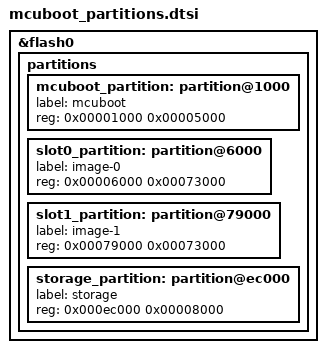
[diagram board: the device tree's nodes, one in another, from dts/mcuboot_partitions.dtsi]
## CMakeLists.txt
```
# SPDX-License-Identifier: MIT

cmake_minimum_required(VERSION 3.20.0)

# The Sense Plus shares the XIAO BLE Sense board definition (same nRF52840,
# LEDs, IMU and mic; the Plus only adds extra pads on the underside).
if(NOT DEFINED BOARD)
  set(BOARD xiao_ble/nrf52840/sense)
endif()

find_package(Zephyr REQUIRED HINTS $ENV{ZEPHYR_BASE})
project(xiao_nrf52840_sense_plus)

target_sources(app PRIVATE
  src/main.c
  src/ble_shell.c
  src/blink.c
  src/bonds.c
  src/crash.c
  src/files.c
  src/hid.c
  src/imu.c
  src/sleep.c
)
```

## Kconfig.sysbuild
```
# SPDX-License-Identifier: MIT

# Sign images with the project's key, an ECDSA P-256 private key in PEM format.
# It is taken from the MCUBOOT_SIGNING_KEY environment variable (a path) or,
# when that is not set, from its usual place in the home directory. With
# neither, the build falls back to MCUboot's public development key.
PROJECT_KEY := $(shell,ls ~/.mcuboot/cato2.pem 2>/dev/null)

config BOOT_SIGNATURE_KEY_FILE
	default "$(MCUBOOT_SIGNING_KEY)" if "$(MCUBOOT_SIGNING_KEY)" != ""
	default "$(PROJECT_KEY)" if "$(PROJECT_KEY)" != ""

source "share/sysbuild/Kconfig"
```

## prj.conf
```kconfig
CONFIG_LOG=y

# Bluetooth LE peripheral
CONFIG_BT=y
CONFIG_BT_PERIPHERAL=y
# Until the board has a name of its own: at first boot it becomes Cato_xxxx,
# from the last four digits of its serial number (src/main.c).
CONFIG_BT_DEVICE_NAME="Cato"
# "name" shell command. 26 characters is what fits in the advertising packet.
CONFIG_BT_DEVICE_NAME_DYNAMIC=y
CONFIG_BT_DEVICE_NAME_MAX=26
# The shell prompt is the name followed by ":~$ ".
CONFIG_SHELL_PROMPT_CHANGE=y
CONFIG_SHELL_PROMPT_BUFF_SIZE=32

# Up to three devices at once, so that a computer using the board as a mouse
# or keyboard does not shut out the console and OTA from another device
CONFIG_BT_MAX_CONN=3

# HID over GATT: mouse, keyboard and sensor reports, in two HID services
# (src/hid.c)
CONFIG_BT_HIDS=y
CONFIG_BT_CONN_CTX=y
CONFIG_BT_HIDS_MAX_CLIENT_COUNT=3
CONFIG_BT_HIDS_ATTR_MAX=30
# Pools the service allocates its attributes from. Too small and the service
# is silently registered incomplete, and hosts then ignore it.
CONFIG_BT_GATT_UUID16_POOL_SIZE=80
CONFIG_BT_GATT_CHRC_POOL_SIZE=24
CONFIG_BT_HIDS_DEFAULT_PERM_RW_ENCRYPT=y
# Ask hosts for an 11.25 ms connection interval, the shortest that Apple hosts
# grant (and only to HID devices). Mouse movement and the sensor report rate
# depend on it. A host that refuses simply keeps its own interval.
CONFIG_BT_PERIPHERAL_PREF_MIN_INT=9
CONFIG_BT_PERIPHERAL_PREF_MAX_INT=9
CONFIG_BT_PERIPHERAL_PREF_LATENCY=0
CONFIG_BT_PERIPHERAL_PREF_TIMEOUT=400
# Several reports per connection event: pack the reports queued within a
# millisecond into one packet for hosts that support it, and ask for the 2 Mbit
# radio mode, which halves the time each packet takes
CONFIG_BT_GATT_NOTIFY_MULTIPLE=y
CONFIG_BT_USER_PHY_UPDATE=y
# Largest packets: ask each host for a 498-byte ATT MTU (the default is 23)
CONFIG_BT_L2CAP_TX_MTU=498
CONFIG_BT_BUF_ACL_RX_SIZE=502
CONFIG_BT_BUF_ACL_TX_SIZE=502
CONFIG_BT_GATT_CLIENT=y
CONFIG_BT_GATT_AUTO_UPDATE_MTU=y
# Room to queue a burst of reports between connection events
CONFIG_BT_L2CAP_TX_BUF_COUNT=8
CONFIG_BT_BUF_ACL_TX_COUNT=8
CONFIG_BT_CONN_TX_MAX=8
CONFIG_BT_CTLR_SDC_TX_PACKET_COUNT=8
# Generic Human Interface Device
CONFIG_BT_DEVICE_APPEARANCE=960
# Hosts expect a Device Information Service with a PnP ID beside HID. The IDs
# are the pid.codes test pair: replace them with your own before shipping.
CONFIG_BT_DIS=y
CONFIG_BT_DIS_PNP=y
CONFIG_BT_DIS_PNP_VID_SRC=2
CONFIG_BT_DIS_PNP_VID=0x1209
CONFIG_BT_DIS_PNP_PID=0x0001
CONFIG_BT_DIS_PNP_VER=0x0001
# The serial number is the chip's unique ID, filled in at boot (src/main.c)
CONFIG_BT_DIS_SERIAL_NUMBER=y
CONFIG_BT_DIS_SETTINGS=y
CONFIG_BT_DIS_STR_MAX=32
CONFIG_SETTINGS_RUNTIME=y
CONFIG_BT_DIS_MANUF_NAME_STR="Auli.Tech"
CONFIG_BT_DIS_MODEL_NUMBER_STR="XIAO nRF52840 Sense Plus"

# Pairing: the console and OTA services need an encrypted link. Up to five
# bonded devices are remembered across resets (see src/bonds.c).
CONFIG_BT_SMP=y
CONFIG_BT_MAX_PAIRED=5
CONFIG_BT_SETTINGS=y
CONFIG_BT_SMP_APP_PAIRING_ACCEPT=y
# Let a bonded device that has forgotten the board pair again.
CONFIG_BT_SMP_ALLOW_UNAUTH_OVERWRITE=y
CONFIG_MCUMGR_TRANSPORT_BT_PERM_RW_ENCRYPT=y

# Console: Zephyr shell (and log output) over Bluetooth (src/ble_shell.c) and
# over the USB CDC ACM serial port
CONFIG_SHELL=y
CONFIG_SHELL_BACKEND_SERIAL=y
CONFIG_RING_BUFFER=y

# "bootloader" shell command
CONFIG_REBOOT=y

# OTA firmware upgrade: MCUmgr/SMP over Bluetooth into the MCUboot secondary slot
CONFIG_NCS_SAMPLE_MCUMGR_BT_OTA_DFU=y

# On-board LSM6DS3TR-C IMU, driven directly over I2C by src/imu.c rather than
# by the Zephyr sensor driver, so that every register can be configured
CONFIG_I2C=y
CONFIG_CBPRINTF_FP_SUPPORT=y

# "sleep" shell command (System OFF), and telling a motion wake-up from a reset
CONFIG_POWEROFF=y
CONFIG_HWINFO=y

# Persistent settings (name, bonds, blink, IMU configuration) in the storage
# partition
CONFIG_FLASH=y
CONFIG_FLASH_MAP=y
CONFIG_NVS=y
CONFIG_SETTINGS=y
CONFIG_SETTINGS_NVS=y

# The Bluetooth transmit thread peaked at 676 of its default 768 bytes.
CONFIG_BT_TX_PROCESSOR_STACK_SIZE=1024

# Files: LittleFS on the 2 MB QSPI flash (src/files.c), which sleeps when idle
CONFIG_FILE_SYSTEM=y
CONFIG_FILE_SYSTEM_LITTLEFS=y
CONFIG_PM_DEVICE=y
CONFIG_PM_DEVICE_RUNTIME=y

# File transfer over Bluetooth: MCUmgr's file commands, with src/files.c
# deciding which transfers may start and told when each piece is done. Only
# sending and fetching are offered, not file status or hashes.
CONFIG_MCUMGR_GRP_FS=y
CONFIG_MCUMGR_GRP_FS_MAX_FILE_SIZE_4GB=y
CONFIG_MCUMGR_GRP_FS_FILE_STATUS=n
CONFIG_MCUMGR_GRP_FS_CHECKSUM_HASH=n
CONFIG_MCUMGR_MGMT_NOTIFICATION_HOOKS=y
CONFIG_MCUMGR_GRP_FS_FILE_ACCESS_HOOK=y
CONFIG_MCUMGR_SMP_COMMAND_STATUS_HOOKS=y
# A piece of a download is read into a buffer on the MCUmgr thread's stack.
CONFIG_MCUMGR_GRP_FS_DL_CHUNK_SIZE_LIMIT=y
CONFIG_MCUMGR_GRP_FS_DL_CHUNK_SIZE=1024
CONFIG_MCUMGR_TRANSPORT_WORKQUEUE_STACK_SIZE=6144
# The "files" commands run file system calls on the shell threads.
CONFIG_SHELL_STACK_SIZE=4096
```

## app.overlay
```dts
/* SPDX-License-Identifier: MIT */

#include "dts/mcuboot_partitions.dtsi"

/ {
	chosen {
		zephyr,code-partition = &slot0_partition;
	};
};

/*
 * The board's 2 MB QSPI flash holds a file system (src/files.c), all of it.
 * The chip is put in deep power-down whenever it is not in use.
 */
&p25q16h {
	zephyr,pm-device-runtime-auto;

	partitions {
		compatible = "fixed-partitions";
		#address-cells = <1>;
		#size-cells = <1>;

		files_partition: partition@0 {
			label = "files";
			reg = <0x00000000 0x00200000>;
		};
	};
};
```

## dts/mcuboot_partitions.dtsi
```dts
/*
 * SPDX-License-Identifier: MIT
 *
 * Flash layout: MCUboot chain-loaded by the stock Adafruit UF2 bootloader.
 *
 *   0x00000  MBR (the UF2 bootloader's, left in place)
 *   0x01000  MCUboot
 *   0x06000  slot 0: running image
 *   0x79000  slot 1: OTA download
 *   0xec000  settings storage
 *   0xf4000  Adafruit UF2 bootloader
 *
 * There is no SoftDevice: Zephyr has its own Bluetooth stack. The UF2
 * bootloader starts whatever follows the MBR when it finds none, so MCUboot
 * takes the SoftDevice's place, and writing usb-upgrade.uf2 to a board that
 * still has one overwrites it.
 *
 * MCUboot is built to be small (sysbuild/mcuboot.conf) and has the least
 * whole number of pages it fits in, with some to spare. The settings have the
 * eight pages their store uses and no more. They used to start a page lower,
 * at 0xeb000, with a ninth page that was never written: the firmware carries
 * them across the first time it starts (see storage_follow_layout() in
 * src/main.c), so they survive the move.
 *
 * Included by both the application and the MCUboot overlay so the two images
 * always agree on the layout. sysbuild.cmake names the ends of the slots too.
 */

/delete-node/ &code_partition;
/delete-node/ &storage_partition;

&flash0 {
	partitions {
		mcuboot_partition: partition@1000 {
			label = "mcuboot";
			reg = <0x00001000 0x00005000>;
		};

		slot0_partition: partition@6000 {
			label = "image-0";
			reg = <0x00006000 0x00073000>;
		};

		slot1_partition: partition@79000 {
			label = "image-1";
			reg = <0x00079000 0x00073000>;
		};

		storage_partition: partition@ec000 {
			label = "storage";
			reg = <0x000ec000 0x00008000>;
		};
	};
};
```

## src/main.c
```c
/*
 * SPDX-License-Identifier: MIT
 */

#include <ctype.h>
#include <string.h>

#include <zephyr/kernel.h>
#include <zephyr/bluetooth/bluetooth.h>
#include <zephyr/bluetooth/conn.h>
#include <zephyr/bluetooth/hci.h>
#include <zephyr/dfu/mcuboot.h>
#include <zephyr/drivers/hwinfo.h>
#include <zephyr/logging/log.h>
#include <zephyr/settings/settings.h>
#include <zephyr/shell/shell.h>
#include <zephyr/shell/shell_uart.h>
#include <zephyr/storage/flash_map.h>
#include <zephyr/sys/reboot.h>
#include <zephyr/drivers/flash.h>
#include <hal/nrf_power.h>
#include <nrfx_nvmc.h>
#include <app_version.h>

#include "app.h"

LOG_MODULE_REGISTER(app, LOG_LEVEL_INF);

/* Value the Adafruit bootloader looks for in GPREGRET to stay in UF2 mode. */
#define UF2_BOOTLOADER_MAGIC 0x57

/* How long a new connection gets to encrypt the link before it is dropped. */
#define SECURITY_TIMEOUT_MS 30000

static struct k_work adv_work;
static struct k_work_delayable security_timeout_work;

/* Connections that have not encrypted the link yet, and when they run out of time. */
static struct {
	struct bt_conn *conn;
	int64_t deadline;
} unsecured[CONFIG_BT_MAX_CONN];
static K_MUTEX_DEFINE(unsecured_lock);

static const uint8_t ad_flags[] = { BT_LE_AD_GENERAL | BT_LE_AD_NO_BREDR };

/* Scan response: the services hosts look for, and what kind of device this is. */
static const struct bt_data sd[] = {
	BT_DATA_BYTES(BT_DATA_UUID128_ALL, APP_UUID_NUS_SERVICE_VAL),
	BT_DATA_BYTES(BT_DATA_UUID16_ALL, BT_UUID_16_ENCODE(BT_UUID_HIDS_VAL)),
	BT_DATA_BYTES(BT_DATA_GAP_APPEARANCE,
		      BT_BYTES_LIST_LE16(CONFIG_BT_DEVICE_APPEARANCE)),
};

/* The advertised name can change at run time, so the data is built on demand. */
static void build_ad(struct bt_data ad[2])
{
	const char *name = bt_get_name();

	ad[0] = (struct bt_data)BT_DATA(BT_DATA_FLAGS, ad_flags, sizeof(ad_flags));
	ad[1] = (struct bt_data)BT_DATA(BT_DATA_NAME_COMPLETE, name, strlen(name));
}

/* Advertises whenever there is room for another connection. */
static void adv_work_handler(struct k_work *work)
{
	struct bt_data ad[2];
	int err;

	build_ad(ad);
	err = bt_le_adv_start(BT_LE_ADV_CONN_FAST_2, ad, ARRAY_SIZE(ad), sd, ARRAY_SIZE(sd));
	if (err && err != -EALREADY && err != -ENOMEM && err != -ECONNREFUSED) {
		LOG_ERR("Advertising failed to start (err %d)", err);
	}
}

static void unsecured_remove(struct bt_conn *conn)
{
	k_mutex_lock(&unsecured_lock, K_FOREVER);
	ARRAY_FOR_EACH(unsecured, i) {
		if (unsecured[i].conn == conn) {
			bt_conn_unref(unsecured[i].conn);
			unsecured[i].conn = NULL;
		}
	}
	k_mutex_unlock(&unsecured_lock);
}

/* Drops connections that have not encrypted in time, so they cannot sit on a slot. */
static void security_timeout_handler(struct k_work *work)
{
	int64_t now = k_uptime_get();
	int64_t next = INT64_MAX;

	k_mutex_lock(&unsecured_lock, K_FOREVER);
	ARRAY_FOR_EACH(unsecured, i) {
		if (unsecured[i].conn == NULL) {
			continue;
		}
		if (unsecured[i].deadline <= now) {
			LOG_WRN("Link not encrypted in time, disconnecting");
			bt_conn_disconnect(unsecured[i].conn, BT_HCI_ERR_AUTH_FAIL);
			/* Removed from the list when the disconnection completes. */
			unsecured[i].deadline = INT64_MAX;
		} else {
			next = MIN(next, unsecured[i].deadline);
		}
	}
	k_mutex_unlock(&unsecured_lock);

	if (next != INT64_MAX) {
		k_work_reschedule(&security_timeout_work, K_MSEC(next - now));
	}
}

static void connected(struct bt_conn *conn, uint8_t err)
{
	if (err) {
		LOG_ERR("Connection failed, err 0x%02x %s", err, bt_hci_err_to_str(err));
		return;
	}

	LOG_INF("Connected");

	err = hid_connected(conn);
	if (err) {
		LOG_WRN("HID service could not take the connection (err %d)", err);
	}

	/*
	 * Ask the peer to encrypt the link: a bonded peer reuses its key, a new
	 * one pairs. The shell, OTA and HID services refuse access until then.
	 */
	err = bt_conn_set_security(conn, BT_SECURITY_L2);
	if (err) {
		LOG_WRN("Could not request encryption (err %d)", err);
	}

	k_mutex_lock(&unsecured_lock, K_FOREVER);
	ARRAY_FOR_EACH(unsecured, i) {
		if (unsecured[i].conn == NULL) {
			unsecured[i].conn = bt_conn_ref(conn);
			unsecured[i].deadline = k_uptime_get() + SECURITY_TIMEOUT_MS;
			break;
		}
	}
	k_mutex_unlock(&unsecured_lock);
	k_work_schedule(&security_timeout_work, K_MSEC(SECURITY_TIMEOUT_MS));

	/* Twice the data rate where the host supports it; harmless where not. */
	(void)bt_conn_le_phy_update(conn, BT_CONN_LE_PHY_PARAM_2M);

	/* Keep advertising for further devices. */
	k_work_submit(&adv_work);
}

static void security_changed(struct bt_conn *conn, bt_security_t level,
			     enum bt_security_err err)
{
	if (err || level < BT_SECURITY_L2) {
		LOG_WRN("Link not secured (%s), disconnecting", bt_security_err_to_str(err));
		bt_conn_disconnect(conn, BT_HCI_ERR_AUTH_FAIL);
		return;
	}

	LOG_INF("Link encrypted");
	unsecured_remove(conn);
}

static void disconnected(struct bt_conn *conn, uint8_t reason)
{
	LOG_INF("Disconnected, reason 0x%02x %s", reason, bt_hci_err_to_str(reason));

	unsecured_remove(conn);
	hid_disconnected(conn);
}

/* The chip's unique ID in hex, once set_serial_number() has read it. */
static char serial[2 * 8 + 1];

/* Device Information Service serial number: the chip's unique ID, in hex. */
static void set_serial_number(void)
{
	uint8_t id[(sizeof(serial) - 1) / 2];
	ssize_t len = hwinfo_get_device_id(id, sizeof(id));
	int err;

	if (len <= 0) {
		LOG_WRN("No device ID for the serial number (err %d)", (int)len);
		return;
	}

	bin2hex(id, len, serial, sizeof(serial));
	err = settings_runtime_set("bt/dis/serial", serial, strlen(serial));
	if (err) {
		LOG_WRN("Could not set the serial number (err %d)", err);
	} else {
		LOG_INF("Serial number %s", serial);
	}
}

/*
 * Both shells prompt with the board's name, so it is plain which board
 * answers. A shell that is busy refuses the change: the USB one is, from boot
 * until a terminal opens its port. So it is tried again until both have it.
 */
static void prompt_work_handler(struct k_work *work);
static K_WORK_DELAYABLE_DEFINE(prompt_work, prompt_work_handler);

static void update_prompt(void)
{
	char prompt[CONFIG_BT_DEVICE_NAME_MAX + sizeof(":~$ ")];
	int err;

	snprintk(prompt, sizeof(prompt), "%s:~$ ", bt_get_name());

	err = ble_shell_set_prompt(prompt);
	if (IS_ENABLED(CONFIG_SHELL_BACKEND_SERIAL) &&
	    shell_prompt_change(shell_backend_uart_get_ptr(), prompt) != 0) {
		err = -EBUSY;
	}
	if (err) {
		k_work_reschedule(&prompt_work, K_MSEC(500));
	}
}

static void prompt_work_handler(struct k_work *work)
{
	update_prompt();
}

/*
 * A board that has not been named is Cato_xxxx, the last four digits of its
 * serial number, so that boards side by side can be told apart. Call after
 * the Bluetooth settings, which hold a name given with "name", are loaded.
 */
static void set_default_name(void)
{
	char name[sizeof("Cato_xxxx")];
	size_t len = strlen(serial);
	int err;

	if (strcmp(bt_get_name(), CONFIG_BT_DEVICE_NAME) != 0 || len < 4) {
		return;
	}

	snprintk(name, sizeof(name), "Cato_%s", &serial[len - 4]);
	for (char *c = &name[5]; *c != '\0'; c++) {
		*c = toupper((unsigned char)*c);
	}

	err = bt_set_name(name);
	if (err) {
		LOG_WRN("Could not set the default name (err %d)", err);
	}
}

static void le_param_updated(struct bt_conn *conn, uint16_t interval, uint16_t latency,
			     uint16_t timeout)
{
	LOG_INF("Connection interval %u.%02u ms", interval * 5 / 4, (interval * 125) % 100);
}

static void recycled(void)
{
	/* The connection object is free again: resume advertising. */
	k_work_submit(&adv_work);
}

BT_CONN_CB_DEFINE(conn_callbacks) = {
	.connected = connected,
	.disconnected = disconnected,
	.security_changed = security_changed,
	.le_param_updated = le_param_updated,
	.recycled = recycled,
};

static int cmd_name(const struct shell *sh, size_t argc, char **argv)
{
	char name[CONFIG_BT_DEVICE_NAME_MAX + 1] = "";
	struct bt_data ad[2];
	size_t len = 0;
	int err;

	if (argc == 1) {
		shell_print(sh, "%s", bt_get_name());
		return 0;
	}

	/* Unquoted words are joined with single spaces. */
	for (size_t i = 1; i < argc; i++) {
		size_t word = strlen(argv[i]);

		if (len + (i > 1) + word > CONFIG_BT_DEVICE_NAME_MAX) {
			shell_error(sh, "Name must be at most %d characters",
				    CONFIG_BT_DEVICE_NAME_MAX);
			return -EINVAL;
		}
		if (i > 1) {
			name[len++] = ' ';
		}
		memcpy(&name[len], argv[i], word);
		len += word;
	}

	for (size_t i = 0; i < len; i++) {
		if (!isprint((unsigned char)name[i])) {
			shell_error(sh, "Name must be plain printable characters");
			return -EINVAL;
		}
	}
	if (len == 0) {
		shell_error(sh, "Name must not be empty");
		return -EINVAL;
	}

	err = bt_set_name(name);
	if (err) {
		shell_error(sh, "Could not set the name (err %d)", err);
		return err;
	}

	/* Takes effect now if advertising; otherwise when advertising next starts. */
	build_ad(ad);
	(void)bt_le_adv_update_data(ad, ARRAY_SIZE(ad), sd, ARRAY_SIZE(sd));
	update_prompt();

	/* Bluetooth stores the name in settings itself. */
	return 0;
}

SHELL_CMD_ARG_REGISTER(name, NULL, "[new name]  Show or change the board's Bluetooth name",
		       cmd_name, 1, SHELL_OPT_ARG_CHECK_SKIP);

static int cmd_bootloader(const struct shell *sh, size_t argc, char **argv)
{
	shell_print(sh, "Resetting into the UF2 bootloader...");
	/* Let the message reach the terminal before the link drops. */
	k_msleep(500);

	nrf_power_gpregret_set(NRF_POWER, 0, UF2_BOOTLOADER_MAGIC);
	sys_reboot(SYS_REBOOT_COLD);

	return 0;
}

SHELL_CMD_REGISTER(bootloader, NULL,
		   "Reset into the UF2 bootloader (USB drive) for flashing over USB",
		   cmd_bootloader);

/* Settings subtrees that belong to the application; "bt" is Bluetooth's. */
static const char *const own_subtrees[] = { "app", "blink", "imu", "hid" };

/* Written to GPREGRET2 across the restart that follows erasing foreign storage. */
#define STORAGE_ERASED_MAGIC 0xA5

static int count_setting(const char *key, size_t len, settings_read_cb read_cb, void *cb_arg,
			 void *param)
{
	(*(int *)param)++;
	return 0;
}

/*
 * The settings used to start one flash page lower than they do now, in a
 * partition of nine pages of which their store (NVS, eight sectors of a page
 * each) only ever used the first eight. The partition is now those eight
 * pages moved up by one, which gives the page below to the firmware slots.
 *
 * Seven of the store's eight pages are therefore already in place. The
 * eighth, its old first page, is now the last page of slot 1, and is copied
 * here to the one page the store did not have before: the new last page.
 * The store is a ring of sectors, so its first sector turning up as its last
 * is the same ring, and everything in it is found as before.
 *
 * This is done once, before the settings are first read. A word in the UICR
 * (which keeps its value through upgrades and resets, and can be written
 * only once) records that it has been. Until then every start goes through
 * it again, and each step leaves things so that the next start can pick up
 * from wherever a power cut left them: the old page is erased only after its
 * copy has been read back and compared, and the word is written last.
 */
#define FLASH_PAGE 4096
#define OLD_FIRST_PAGE (PARTITION_OFFSET(storage_partition) - FLASH_PAGE)
#define NEW_LAST_PAGE \
	(PARTITION_OFFSET(storage_partition) + PARTITION_SIZE(storage_partition) - FLASH_PAGE)
#define STORAGE_MOVED (&NRF_UICR->CUSTOMER[0])
#define STORAGE_MOVED_MARK 0x00000001

BUILD_ASSERT(PARTITION_SIZE(storage_partition) == 8 * FLASH_PAGE);
BUILD_ASSERT(OLD_FIRST_PAGE == PARTITION_OFFSET(slot1_partition) +
				PARTITION_SIZE(slot1_partition) - FLASH_PAGE);

/* -1 on a read error, 1 if the page is erased or the same as another, else 0. */
static int page_is(const struct device *flash, off_t page, const off_t *same_as)
{
	uint8_t a[128];
	uint8_t b[sizeof(a)];

	memset(b, 0xff, sizeof(b));
	for (off_t at = 0; at < FLASH_PAGE; at += sizeof(a)) {
		if (flash_read(flash, page + at, a, sizeof(a)) != 0 ||
		    (same_as != NULL && flash_read(flash, *same_as + at, b, sizeof(b)) != 0)) {
			return -1;
		}
		if (memcmp(a, b, sizeof(a)) != 0) {
			return 0;
		}
	}
	return 1;
}

static void storage_follow_layout(void)
{
	const struct device *flash = DEVICE_DT_GET(DT_CHOSEN(zephyr_flash_controller));
	const off_t from = OLD_FIRST_PAGE;
	const off_t to = NEW_LAST_PAGE;
	uint8_t chunk[128];
	int blank;

	if (*STORAGE_MOVED != 0xffffffff) {
		return;
	}
	if (!device_is_ready(flash)) {
		return;
	}

	blank = page_is(flash, from, NULL);
	if (blank < 0) {
		return;
	}
	if (!blank) {
		/* Anything already in the new page is a copy that was cut short. */
		if (page_is(flash, to, NULL) != 1 && flash_erase(flash, to, FLASH_PAGE) != 0) {
			return;
		}
		for (off_t at = 0; at < FLASH_PAGE; at += sizeof(chunk)) {
			if (flash_read(flash, from + at, chunk, sizeof(chunk)) != 0 ||
			    flash_write(flash, to + at, chunk, sizeof(chunk)) != 0) {
				return;
			}
		}
		if (page_is(flash, to, &from) != 1) {
			return;
		}
		/* The page is slot 1's now, where MCUboot expects to find it blank. */
		if (flash_erase(flash, from, FLASH_PAGE) != 0) {
			return;
		}
		LOG_INF("Settings moved to their place in the new flash layout");
	}

	nrfx_nvmc_word_write((uint32_t)STORAGE_MOVED, STORAGE_MOVED_MARK);
}

/* Erases the whole settings partition. */
static int erase_storage(void)
{
	const struct flash_area *storage;
	int err = flash_area_open(PARTITION_ID(storage_partition), &storage);

	if (!err) {
		err = flash_area_flatten(storage, 0, storage->fa_size);
		flash_area_close(storage);
	}
	return err;
}

static int cmd_reboot(const struct shell *sh, size_t argc, char **argv)
{
	shell_print(sh, "Restarting...");
	/* Let the message reach the terminal before the link drops. */
	k_msleep(500);

	sys_reboot(SYS_REBOOT_COLD);

	return 0;
}

SHELL_CMD_REGISTER(reboot, NULL, "Restart the board", cmd_reboot);

static int cmd_version(const struct shell *sh, size_t argc, char **argv)
{
	shell_print(sh, "firmware %s", APP_VERSION_STRING);
	/*
	 * Where in flash the image runs from. An image built for another flash
	 * layout runs from somewhere else and cannot be installed over
	 * Bluetooth: MyCato reads this to tell. Firmware that does not print it
	 * is at 0x33000.
	 */
	shell_print(sh, "image slot at 0x%x", (unsigned int)PARTITION_OFFSET(slot0_partition));

	return 0;
}

SHELL_CMD_REGISTER(version, NULL, "Show the firmware version", cmd_version);

/*
 * Everything the board remembers (name, blink, IMU and HID settings, pairing
 * switch and the bonds themselves) lives in the storage partition, so erasing
 * it and restarting brings back every default at once.
 */
static int cmd_factory_reset(const struct shell *sh, size_t argc, char **argv)
{
	int err;

	if (argc != 2 || strcmp(argv[1], "confirm") != 0) {
		shell_error(sh, "This erases all settings and paired devices. "
				"To go ahead: factory_reset confirm");
		return -EINVAL;
	}

	shell_print(sh, "Erasing all settings and paired devices, then restarting...");
	k_msleep(500);

	err = erase_storage();
	if (err) {
		shell_error(sh, "Could not erase the settings (err %d)", err);
		return err;
	}

	sys_reboot(SYS_REBOOT_COLD);

	return 0;
}

SHELL_CMD_ARG_REGISTER(factory_reset, NULL,
		       "confirm  Erase all settings and paired devices, then restart",
		       cmd_factory_reset, 1, 1);

int main(void)
{
	uint32_t reset_cause;
	int own_settings = 0;
	bool fresh;
	int err;

	LOG_INF("XIAO nRF52840 Sense Plus, firmware %s", APP_VERSION_STRING);
	crash_report();

	storage_follow_layout();

	/*
	 * Application settings first; the Bluetooth ones (bonds, name) can only
	 * be loaded once Bluetooth is enabled.
	 */
	err = settings_subsys_init();
	if (!err) {
		for (size_t i = 0; i < ARRAY_SIZE(own_subtrees); i++) {
			(void)settings_load_subtree_direct(own_subtrees[i], count_setting,
							   &own_settings);
		}
	}

	/*
	 * A board that ran other firmware before, such as a legacy Cato, has
	 * that firmware's data where the settings live: unreadable, or readable
	 * but not ours, with Bluetooth bonds and a name that are not this
	 * firmware's. Either way none of this firmware's own settings are in
	 * it, so it is erased, once, and the board restarts with a clean slate.
	 * The marker in a retained register stops that from repeating.
	 */
	fresh = nrf_power_gpregret_get(NRF_POWER, 1) == STORAGE_ERASED_MAGIC;
	nrf_power_gpregret_set(NRF_POWER, 1, 0);
	if ((err || own_settings == 0) && !fresh) {
		LOG_WRN("No settings of this firmware in storage: erasing it");
		if (erase_storage() == 0) {
			nrf_power_gpregret_set(NRF_POWER, 1, STORAGE_ERASED_MAGIC);
			sys_reboot(SYS_REBOOT_COLD);
		}
	}
	if (!err && own_settings == 0) {
		/* From now on the storage is recognisably this firmware's. */
		uint8_t owner = 1;

		(void)settings_save_one("app/owner", &owner, sizeof(owner));
	}

	for (size_t i = 0; !err && i < ARRAY_SIZE(own_subtrees); i++) {
		err = settings_load_subtree(own_subtrees[i]);
	}
	if (err) {
		LOG_ERR("Could not load settings, using defaults (err %d)", err);
	}

	/* The only pin armed to wake the SoC from sleep is the IMU's interrupt. */
	if (hwinfo_get_reset_cause(&reset_cause) == 0) {
		if (reset_cause & RESET_LOW_POWER_WAKE) {
			LOG_INF("Woken from sleep by motion");
		}
		hwinfo_clear_reset_cause();
	}

	imu_init();
	/* The board works without its files: the failure is logged there. */
	(void)files_init();

	k_work_init(&adv_work, adv_work_handler);
	k_work_init_delayable(&security_timeout_work, security_timeout_handler);

	err = bonds_init();
	if (err) {
		LOG_ERR("Could not set up pairing (err %d)", err);
		return 0;
	}

	err = hid_init();
	if (err) {
		LOG_ERR("Could not set up the HID service (err %d)", err);
		return 0;
	}

	err = bt_enable(NULL);
	if (err) {
		LOG_ERR("Bluetooth enable failed (err %d)", err);
		return 0;
	}

	err = settings_load_subtree("bt");
	if (err) {
		LOG_ERR("Could not load Bluetooth settings (err %d)", err);
	}
	set_serial_number();
	set_default_name();

	err = ble_shell_init();
	if (err) {
		LOG_ERR("Failed to start the Bluetooth shell (err %d)", err);
		return 0;
	}
	update_prompt();

	k_work_submit(&adv_work);

	/*
	 * Bluetooth is up, so this image can receive another OTA update: mark
	 * it as good. An image that never gets here is reverted by MCUboot on
	 * the next reset.
	 */
	if (!boot_is_img_confirmed()) {
		err = boot_write_img_confirmed();
		if (err) {
			LOG_ERR("Failed to confirm image (err %d)", err);
		} else {
			LOG_INF("New image confirmed");
		}
	}

	/* The LED is driven from its own thread, see blink.c. */
	return 0;
}
```

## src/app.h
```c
/*
 * SPDX-License-Identifier: MIT
 */

#ifndef APP_H_
#define APP_H_

#include <stdbool.h>
#include <stdint.h>

#include <zephyr/bluetooth/uuid.h>

struct bt_conn;

/* Nordic UART Service, used for the Bluetooth shell and advertised. */
#define APP_UUID_NUS_SERVICE_VAL \
	BT_UUID_128_ENCODE(0x6e400001, 0xb5a3, 0xf393, 0xe0a9, 0xe50e24dcca9e)

/*
 * ble_shell.c: start the Bluetooth shell (once, after Bluetooth is enabled).
 * Every connected device that subscribes shares the one shell.
 */
int ble_shell_init(void);

/* ble_shell.c: change the Bluetooth shell's prompt. */
int ble_shell_set_prompt(const char *prompt);

/*
 * hid.c: register the HID service (before Bluetooth is enabled) and tell it
 * about each connection.
 */
int hid_init(void);
int hid_connected(struct bt_conn *conn);
void hid_disconnected(struct bt_conn *conn);

/* blink.c: turn the LED off and stop blinking, ahead of power-off. */
void blink_stop(void);

/*
 * imu.c: reset the IMU and apply the saved (or default) configuration. Call
 * after settings have been loaded.
 */
int imu_init(void);

/* One reading with the current ranges: acceleration in g, rotation in deg/s. */
int imu_sample(float accel_g[3], float gyro_dps[3]);

/* Put the accelerometer and gyroscope in power-down. */
int imu_power_down(void);

/*
 * Leave only the low-power accelerometer running and raise INT1 when the
 * acceleration changes by more than threshold_mg. The threshold actually set
 * (rounded to what the chip supports) is written back.
 */
int imu_arm_wake(uint32_t *threshold_mg);

/* bonds.c: register the pairing policy. Call before Bluetooth is enabled. */
int bonds_init(void);

#include <zephyr/bluetooth/addr.h>

/* bonds.c: the name given to a bonded device, or NULL if it has none. */
const char *bonds_name(const bt_addr_le_t *addr);

#include <stddef.h>

/*
 * files.c: mount the file system on the QSPI flash, which MyCato and the
 * "files" shell command also reach. See there for how they are kept from
 * getting in each other's way.
 */
int files_init(void);

/*
 * The firmware's own access to a file, by its name alone. files_read() reads
 * up to size bytes from its start and gives the number read. files_write()
 * replaces the whole file, or leaves it as it was: never half of each. It
 * gives -EBUSY while the file is being downloaded over Bluetooth.
 */
int files_read(const char *name, void *buf, size_t size, size_t *len);
int files_write(const char *name, const void *data, size_t len);

/* crash.c: log the crash that caused the previous restart, if any. */
void crash_report(void);

#endif /* APP_H_ */
```

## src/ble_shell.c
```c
/*
 * SPDX-License-Identifier: MIT
 *
 * Zephyr shell over Bluetooth, using the Nordic UART Service (NUS) layout so
 * that existing UART terminal apps work.
 *
 * The service is defined here rather than taken from the SDK because its
 * writable attributes must require an encrypted link: a device that has not
 * paired can neither send shell input nor subscribe to shell output, and its
 * attempt is answered with the error that makes phones and computers pair.
 *
 * The shell runs from boot and is shared: input from any connected device is
 * accepted and output goes to every device that has subscribed. It is dropped
 * while none has.
 */

#include <zephyr/kernel.h>
#include <zephyr/bluetooth/bluetooth.h>
#include <zephyr/bluetooth/conn.h>
#include <zephyr/bluetooth/gatt.h>
#include <zephyr/bluetooth/uuid.h>
#include <zephyr/logging/log.h>
#include <zephyr/shell/shell.h>
#include <zephyr/sys/ring_buffer.h>

#include "app.h"

LOG_MODULE_REGISTER(ble_shell, LOG_LEVEL_INF);

#define UUID_NUS_RX BT_UUID_DECLARE_128( \
	BT_UUID_128_ENCODE(0x6e400002, 0xb5a3, 0xf393, 0xe0a9, 0xe50e24dcca9e))
#define UUID_NUS_TX BT_UUID_DECLARE_128( \
	BT_UUID_128_ENCODE(0x6e400003, 0xb5a3, 0xf393, 0xe0a9, 0xe50e24dcca9e))

/* Index of the TX characteristic value in the service's attribute table. */
#define TX_ATTR_INDEX 2

/* ATT header: opcode and attribute handle. */
#define NOTIFY_OVERHEAD 3

RING_BUF_DECLARE(rx_ringbuf, 256);

static shell_transport_handler_t shell_handler;
static void *shell_context;

static ssize_t on_rx_write(struct bt_conn *conn, const struct bt_gatt_attr *attr,
			   const void *buf, uint16_t len, uint16_t offset, uint8_t flags)
{
	uint32_t stored = ring_buf_put(&rx_ringbuf, buf, len);

	if (stored < len) {
		LOG_WRN("Input overflow, %u bytes dropped", len - stored);
	}
	if (shell_handler != NULL) {
		shell_handler(SHELL_TRANSPORT_EVT_RX_RDY, shell_context);
	}

	return len;
}

BT_GATT_SERVICE_DEFINE(nus_service,
	BT_GATT_PRIMARY_SERVICE(BT_UUID_DECLARE_128(APP_UUID_NUS_SERVICE_VAL)),
	BT_GATT_CHARACTERISTIC(UUID_NUS_TX, BT_GATT_CHRC_NOTIFY, BT_GATT_PERM_NONE,
			       NULL, NULL, NULL),
	BT_GATT_CCC(NULL, BT_GATT_PERM_READ | BT_GATT_PERM_WRITE_ENCRYPT),
	BT_GATT_CHARACTERISTIC(UUID_NUS_RX,
			       BT_GATT_CHRC_WRITE | BT_GATT_CHRC_WRITE_WITHOUT_RESP,
			       BT_GATT_PERM_WRITE_ENCRYPT, NULL, on_rx_write, NULL),
);

struct output {
	const uint8_t *data;
	size_t length;
};

static void write_to(struct bt_conn *conn, void *user_data)
{
	const struct bt_gatt_attr *tx_attr = &nus_service.attrs[TX_ATTR_INDEX];
	const struct output *output = user_data;
	size_t sent = 0;

	while (sent < output->length &&
	       bt_gatt_is_subscribed(conn, tx_attr, BT_GATT_CCC_NOTIFY)) {
		size_t chunk = MIN(output->length - sent,
				   bt_gatt_get_mtu(conn) - NOTIFY_OVERHEAD);

		if (bt_gatt_notify(conn, tx_attr, &output->data[sent], chunk) != 0) {
			break;
		}
		sent += chunk;
	}
}

/* ----------------------------------------------------- shell transport --- */

static int transport_init(const struct shell_transport *transport, const void *config,
			  shell_transport_handler_t handler, void *context)
{
	shell_handler = handler;
	shell_context = context;

	return 0;
}

static int transport_uninit(const struct shell_transport *transport)
{
	return 0;
}

static int transport_enable(const struct shell_transport *transport, bool blocking_tx)
{
	return 0;
}

static int transport_write(const struct shell_transport *transport, const void *data,
			   size_t length, size_t *count)
{
	struct output output = { .data = data, .length = length };

	/* Everything is always "written": with nobody listening it is dropped. */
	*count = length;

	if (!k_is_in_isr()) {
		bt_conn_foreach(BT_CONN_TYPE_LE, write_to, &output);
	}

	if (shell_handler != NULL) {
		shell_handler(SHELL_TRANSPORT_EVT_TX_RDY, shell_context);
	}

	return 0;
}

static int transport_read(const struct shell_transport *transport, void *data,
			  size_t length, size_t *count)
{
	*count = ring_buf_get(&rx_ringbuf, data, length);

	return 0;
}

static const struct shell_transport_api transport_api = {
	.init = transport_init,
	.uninit = transport_uninit,
	.enable = transport_enable,
	.write = transport_write,
	.read = transport_read,
};

static struct shell_transport ble_transport = {
	.api = &transport_api,
};

/* The prompt is replaced by the board's name once that is known. */
SHELL_DEFINE(shell_ble, "bt_nus:~$ ", &ble_transport, 256, 0, SHELL_FLAG_OLF_CRLF);

int ble_shell_set_prompt(const char *prompt)
{
	return shell_prompt_change(&shell_ble, prompt);
}

int ble_shell_init(void)
{
	static const struct shell_backend_config_flags flags = SHELL_DEFAULT_BACKEND_CONFIG_FLAGS;

	return shell_init(&shell_ble, NULL, flags, true, LOG_LEVEL_INF);
}
```

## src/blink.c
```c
/*
 * SPDX-License-Identifier: MIT
 *
 * RGB LED blinker with a shell command to change its rate and pattern.
 * Both values are kept in the settings storage partition across resets.
 */

#include <string.h>

#include <zephyr/kernel.h>
#include <zephyr/drivers/gpio.h>
#include <zephyr/logging/log.h>
#include <zephyr/settings/settings.h>
#include <zephyr/shell/shell.h>

#include "app.h"

LOG_MODULE_REGISTER(blink, LOG_LEVEL_INF);

#define RATE_MIN_MS     20
#define RATE_MAX_MS     60000
#define RATE_DEFAULT_MS 1000

#define PATTERN_MAX_LEN 32
#define PATTERN_DEFAULT "rgb"
#define PATTERN_HELP \
	"r g b = red green blue, y c m = yellow cyan magenta, w = white, - = off"

#define RED   BIT(0)
#define GREEN BIT(1)
#define BLUE  BIT(2)

/* Indexed by the bits above. */
static const struct gpio_dt_spec leds[] = {
	GPIO_DT_SPEC_GET(DT_ALIAS(led0), gpios),
	GPIO_DT_SPEC_GET(DT_ALIAS(led1), gpios),
	GPIO_DT_SPEC_GET(DT_ALIAS(led2), gpios),
};

static K_MUTEX_DEFINE(lock);
static K_SEM_DEFINE(changed, 0, 1);
static uint32_t rate_ms = RATE_DEFAULT_MS;
static char pattern[PATTERN_MAX_LEN + 1] = PATTERN_DEFAULT;

/* LEDs lit for one pattern character, or -1 if the character is not valid. */
static int step_leds(char c)
{
	switch (c) {
	case 'r': return RED;
	case 'g': return GREEN;
	case 'b': return BLUE;
	case 'y': return RED | GREEN;
	case 'c': return GREEN | BLUE;
	case 'm': return RED | BLUE;
	case 'w': return RED | GREEN | BLUE;
	case '-': return 0;
	default:  return -1;
	}
}

static bool rate_valid(uint32_t ms)
{
	return ms >= RATE_MIN_MS && ms <= RATE_MAX_MS;
}

static bool pattern_valid(const char *p)
{
	size_t len = strlen(p);

	if (len == 0 || len > PATTERN_MAX_LEN) {
		return false;
	}
	for (size_t i = 0; i < len; i++) {
		if (step_leds(p[i]) < 0) {
			return false;
		}
	}
	return true;
}

static void apply_rate(uint32_t ms)
{
	k_mutex_lock(&lock, K_FOREVER);
	rate_ms = ms;
	k_mutex_unlock(&lock);
	k_sem_give(&changed);
}

static void apply_pattern(const char *p)
{
	k_mutex_lock(&lock, K_FOREVER);
	strcpy(pattern, p);
	k_mutex_unlock(&lock);
	k_sem_give(&changed);
}

/* Called when main() loads settings, for each stored "blink/..." value. */
static int blink_settings_set(const char *name, size_t len, settings_read_cb read_cb,
			      void *cb_arg)
{
	ssize_t rc;

	if (settings_name_steq(name, "rate", NULL)) {
		uint32_t ms;

		if (len != sizeof(ms)) {
			return -EINVAL;
		}
		rc = read_cb(cb_arg, &ms, sizeof(ms));
		if (rc < 0) {
			return rc;
		}
		if (rate_valid(ms)) {
			apply_rate(ms);
		}
		return 0;
	}

	if (settings_name_steq(name, "pattern", NULL)) {
		char buf[PATTERN_MAX_LEN + 1] = { 0 };

		if (len > PATTERN_MAX_LEN) {
			return -EINVAL;
		}
		rc = read_cb(cb_arg, buf, len);
		if (rc < 0) {
			return rc;
		}
		if (pattern_valid(buf)) {
			apply_pattern(buf);
		}
		return 0;
	}

	return -ENOENT;
}

SETTINGS_STATIC_HANDLER_DEFINE(blink, "blink", NULL, blink_settings_set, NULL, NULL);

static void blink_thread(void *p1, void *p2, void *p3)
{
	size_t step = 0;

	ARRAY_FOR_EACH(leds, i) {
		if (gpio_is_ready_dt(&leds[i])) {
			gpio_pin_configure_dt(&leds[i], GPIO_OUTPUT_INACTIVE);
		}
	}

	while (1) {
		uint32_t ms;
		int lit;

		k_mutex_lock(&lock, K_FOREVER);
		if (step >= strlen(pattern)) {
			step = 0;
		}
		lit = step_leds(pattern[step]);
		ms = rate_ms;
		k_mutex_unlock(&lock);

		ARRAY_FOR_EACH(leds, i) {
			gpio_pin_set_dt(&leds[i], (lit & BIT(i)) != 0);
		}

		step++;
		if (k_sem_take(&changed, K_MSEC(ms)) == 0) {
			/* New rate or pattern: start over. */
			step = 0;
		}
	}
}

K_THREAD_DEFINE(blink_tid, 2048, blink_thread, NULL, NULL, NULL,
		K_LOWEST_APPLICATION_THREAD_PRIO, 0, 0);

void blink_stop(void)
{
	k_thread_suspend(blink_tid);

	ARRAY_FOR_EACH(leds, i) {
		gpio_pin_set_dt(&leds[i], 0);
	}
}

static int cmd_blink(const struct shell *sh, size_t argc, char **argv)
{
	k_mutex_lock(&lock, K_FOREVER);
	shell_print(sh, "rate %u ms, pattern %s", rate_ms, pattern);
	k_mutex_unlock(&lock);

	return 0;
}

static int cmd_blink_rate(const struct shell *sh, size_t argc, char **argv)
{
	int err = 0;
	unsigned long ms = shell_strtoul(argv[1], 10, &err);
	uint32_t value;

	if (err || !rate_valid(ms)) {
		shell_error(sh, "Rate must be %d to %d ms", RATE_MIN_MS, RATE_MAX_MS);
		return -EINVAL;
	}

	value = ms;
	apply_rate(value);

	err = settings_save_one("blink/rate", &value, sizeof(value));
	if (err) {
		shell_error(sh, "Applied, but not saved (err %d)", err);
		return err;
	}

	return 0;
}

static int cmd_blink_pattern(const struct shell *sh, size_t argc, char **argv)
{
	int err;

	if (!pattern_valid(argv[1])) {
		shell_error(sh, "Pattern must be 1 to %d of: %s", PATTERN_MAX_LEN, PATTERN_HELP);
		return -EINVAL;
	}

	apply_pattern(argv[1]);

	err = settings_save_one("blink/pattern", argv[1], strlen(argv[1]));
	if (err) {
		shell_error(sh, "Applied, but not saved (err %d)", err);
		return err;
	}

	return 0;
}

SHELL_STATIC_SUBCMD_SET_CREATE(blink_cmds,
	SHELL_CMD_ARG(rate, NULL, "<ms>  Time per pattern step", cmd_blink_rate, 2, 0),
	SHELL_CMD_ARG(pattern, NULL, "<steps>  One character per step: " PATTERN_HELP,
		      cmd_blink_pattern, 2, 0),
	SHELL_SUBCMD_SET_END
);

SHELL_CMD_REGISTER(blink, &blink_cmds, "Show or change the LED blink rate and pattern",
		   cmd_blink);
```

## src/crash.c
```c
/*
 * SPDX-License-Identifier: MIT
 *
 * Fatal error handling: record what crashed in RAM that survives the reset,
 * restart, and report it in the log at the next boot. Without this a crash
 * leaves the board frozen until the reset button is pressed.
 */

#include <string.h>

#include <zephyr/kernel.h>
#include <zephyr/fatal.h>
#include <zephyr/logging/log.h>
#include <zephyr/logging/log_ctrl.h>
#include <zephyr/sys/reboot.h>

#include "app.h"

LOG_MODULE_REGISTER(crash, LOG_LEVEL_INF);

#define CRASH_MAGIC 0xc4a54ed1

/*
 * Kept high in RAM, clear of the memory that this firmware, MCUboot and the
 * UF2 bootloader use, so the record survives the trip through both loaders.
 */
#define CRASH_RECORD ((struct crash_record *)0x20030000)

struct crash_record {
	uint32_t magic;
	uint32_t reason;
	uint32_t pc;
	uint32_t lr;
	char thread[16];
};

void k_sys_fatal_error_handler(unsigned int reason, const struct arch_esf *esf)
{
	struct crash_record *record = CRASH_RECORD;
	const char *name = k_is_in_isr() ? "ISR" : k_thread_name_get(k_current_get());

	record->reason = reason;
	record->pc = esf ? esf->basic.pc : 0;
	record->lr = esf ? esf->basic.lr : 0;
	strncpy(record->thread, name ? name : "?", sizeof(record->thread) - 1);
	record->thread[sizeof(record->thread) - 1] = '\0';
	record->magic = CRASH_MAGIC;

	LOG_PANIC();
	sys_reboot(SYS_REBOOT_COLD);
	CODE_UNREACHABLE;
}

void crash_report(void)
{
	struct crash_record *record = CRASH_RECORD;

	if (record->magic != CRASH_MAGIC) {
		return;
	}

	LOG_ERR("Restarted after a crash: reason %u in %s, pc 0x%08x lr 0x%08x",
		record->reason, record->thread, record->pc, record->lr);
	record->magic = 0;
}
```

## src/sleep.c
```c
/*
 * SPDX-License-Identifier: MIT
 *
 * "sleep" shell command: power the SoC off (System OFF) until the reset
 * button is pressed, or until the IMU detects motion. Waking is a reset, so
 * the firmware starts from the beginning.
 */

#include <zephyr/kernel.h>
#include <zephyr/drivers/gpio.h>
#include <zephyr/shell/shell.h>
#include <zephyr/sys/poweroff.h>

#include "app.h"

#define WAKE_DEFAULT_MG 125
#define WAKE_MIN_MG     32
#define WAKE_MAX_MG     1968

static const struct gpio_dt_spec imu_int1 =
	GPIO_DT_SPEC_GET(DT_NODELABEL(lsm6ds3tr_c), irq_gpios);

static void power_off(void)
{
	/* Let the message reach the terminal before the link drops. */
	k_msleep(500);
	blink_stop();
	sys_poweroff();
}

static int cmd_sleep_off(const struct shell *sh, size_t argc, char **argv)
{
	int err = imu_power_down();

	if (err) {
		shell_warn(sh, "Could not power down the IMU (err %d)", err);
	}

	/* Make sure a previous motion sleep cannot wake this one. */
	gpio_pin_interrupt_configure_dt(&imu_int1, GPIO_INT_DISABLE);
	gpio_pin_configure_dt(&imu_int1, GPIO_DISCONNECTED);

	shell_print(sh, "Sleeping until the reset button is pressed...");
	power_off();

	return 0;
}

static int cmd_sleep_motion(const struct shell *sh, size_t argc, char **argv)
{
	uint32_t threshold_mg = WAKE_DEFAULT_MG;
	int err = 0;

	if (argc > 1) {
		threshold_mg = shell_strtoul(argv[1], 10, &err);
		if (err || threshold_mg < WAKE_MIN_MG || threshold_mg > WAKE_MAX_MG) {
			shell_error(sh, "Threshold must be %d to %d mg", WAKE_MIN_MG, WAKE_MAX_MG);
			return -EINVAL;
		}
	}

	if (!gpio_is_ready_dt(&imu_int1)) {
		shell_error(sh, "IMU interrupt pin not ready");
		return -ENODEV;
	}

	err = imu_arm_wake(&threshold_mg);
	if (err) {
		shell_error(sh, "Could not arm the IMU (err %d)", err);
		return err;
	}

	/* A high level on the IMU's INT1 pin wakes the SoC from System OFF. */
	err = gpio_pin_configure_dt(&imu_int1, GPIO_INPUT);
	if (!err) {
		err = gpio_pin_interrupt_configure_dt(&imu_int1, GPIO_INT_LEVEL_ACTIVE);
	}
	if (err) {
		shell_error(sh, "Could not arm the wake-up pin (err %d)", err);
		return err;
	}

	shell_print(sh, "Sleeping until motion above %u mg, or the reset button...",
		    threshold_mg);
	power_off();

	return 0;
}

SHELL_STATIC_SUBCMD_SET_CREATE(sleep_cmds,
	SHELL_CMD(off, NULL, "Deep sleep until the reset button is pressed", cmd_sleep_off),
	SHELL_CMD_ARG(motion, NULL,
		      "[mg]  Sleep until the board is moved (default 125 mg) or reset",
		      cmd_sleep_motion, 1, 1),
	SHELL_SUBCMD_SET_END
);

SHELL_CMD_REGISTER(sleep, &sleep_cmds, "Power down until reset or motion", NULL);
```
